VERSION ""

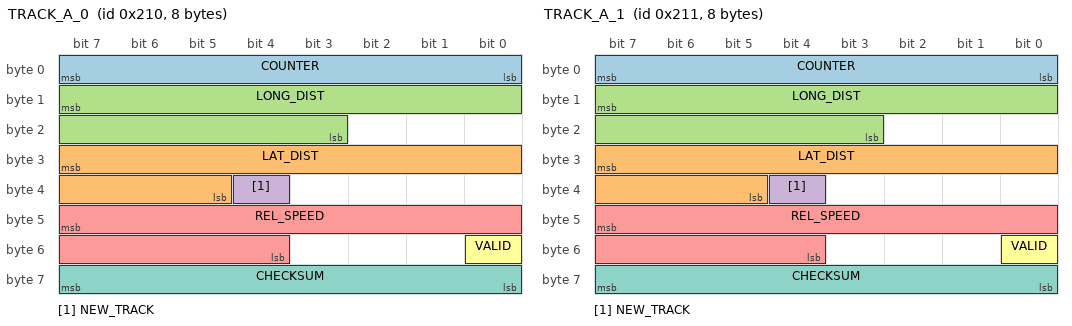
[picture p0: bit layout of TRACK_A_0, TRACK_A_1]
BO_ 528 TRACK_A_0: 8 XXX
 SG_ COUNTER : 7|8@0+ (1,0) [0|255] "" XXX
 SG_ LAT_DIST : 31|11@0- (0.04,0) [-50|50] "m" XXX
 SG_ LONG_DIST : 15|13@0+ (0.04,0) [0|300] "m" XXX
 SG_ NEW_TRACK : 36|1@0+ (1,0) [0|1] "" XXX
 SG_ REL_SPEED : 47|12@0- (0.025,0) [-100|100] "m/s" XXX
 SG_ VALID : 48|1@0+ (1,0) [0|1] "" XXX
 SG_ CHECKSUM : 63|8@0+ (1,0) [0|255] "" XXX

BO_ 529 TRACK_A_1: 8 XXX
 SG_ COUNTER : 7|8@0+ (1,0) [0|255] "" XXX
 SG_ LAT_DIST : 31|11@0- (0.04,0) [-50|50] "m" XXX
 SG_ LONG_DIST : 15|13@0+ (0.04,0) [0|300] "m" XXX
 SG_ NEW_TRACK : 36|1@0+ (1,0) [0|1] "" XXX
 SG_ REL_SPEED : 47|12@0- (0.025,0) [-100|100] "m/s" XXX
 SG_ VALID : 48|1@0+ (1,0) [0|1] "" XXX
 SG_ CHECKSUM : 63|8@0+ (1,0) [0|255] "" XXX

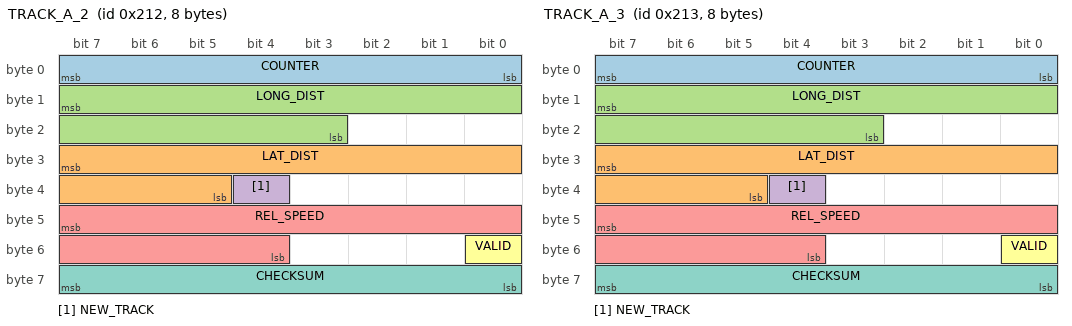
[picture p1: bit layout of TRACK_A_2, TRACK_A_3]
BO_ 530 TRACK_A_2: 8 XXX
 SG_ COUNTER : 7|8@0+ (1,0) [0|255] "" XXX
 SG_ LAT_DIST : 31|11@0- (0.04,0) [-50|50] "m" XXX
 SG_ LONG_DIST : 15|13@0+ (0.04,0) [0|300] "m" XXX
 SG_ NEW_TRACK : 36|1@0+ (1,0) [0|1] "" XXX
 SG_ REL_SPEED : 47|12@0- (0.025,0) [-100|100] "m/s" XXX
 SG_ VALID : 48|1@0+ (1,0) [0|1] "" XXX
 SG_ CHECKSUM : 63|8@0+ (1,0) [0|255] "" XXX

BO_ 531 TRACK_A_3: 8 XXX
 SG_ COUNTER : 7|8@0+ (1,0) [0|255] "" XXX
 SG_ LAT_DIST : 31|11@0- (0.04,0) [-50|50] "m" XXX
 SG_ LONG_DIST : 15|13@0+ (0.04,0) [0|300] "m" XXX
 SG_ NEW_TRACK : 36|1@0+ (1,0) [0|1] "" XXX
 SG_ REL_SPEED : 47|12@0- (0.025,0) [-100|100] "m/s" XXX
 SG_ VALID : 48|1@0+ (1,0) [0|1] "" XXX
 SG_ CHECKSUM : 63|8@0+ (1,0) [0|255] "" XXX

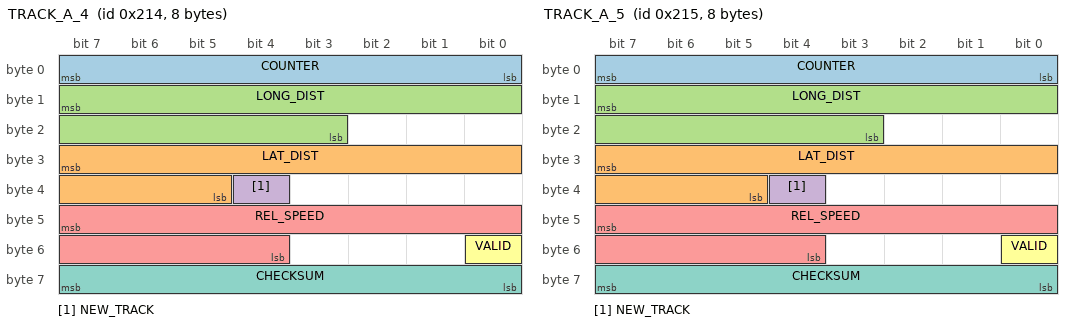
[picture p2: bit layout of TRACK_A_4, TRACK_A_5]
BO_ 532 TRACK_A_4: 8 XXX
 SG_ COUNTER : 7|8@0+ (1,0) [0|255] "" XXX
 SG_ LAT_DIST : 31|11@0- (0.04,0) [-50|50] "m" XXX
 SG_ LONG_DIST : 15|13@0+ (0.04,0) [0|300] "m" XXX
 SG_ NEW_TRACK : 36|1@0+ (1,0) [0|1] "" XXX
 SG_ REL_SPEED : 47|12@0- (0.025,0) [-100|100] "m/s" XXX
 SG_ VALID : 48|1@0+ (1,0) [0|1] "" XXX
 SG_ CHECKSUM : 63|8@0+ (1,0) [0|255] "" XXX

BO_ 533 TRACK_A_5: 8 XXX
 SG_ COUNTER : 7|8@0+ (1,0) [0|255] "" XXX
 SG_ LAT_DIST : 31|11@0- (0.04,0) [-50|50] "m" XXX
 SG_ LONG_DIST : 15|13@0+ (0.04,0) [0|300] "m" XXX
 SG_ NEW_TRACK : 36|1@0+ (1,0) [0|1] "" XXX
 SG_ REL_SPEED : 47|12@0- (0.025,0) [-100|100] "m/s" XXX
 SG_ VALID : 48|1@0+ (1,0) [0|1] "" XXX
 SG_ CHECKSUM : 63|8@0+ (1,0) [0|255] "" XXX

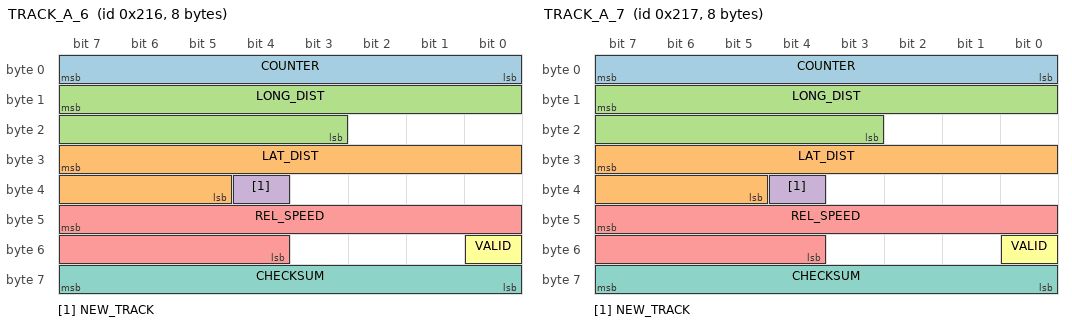
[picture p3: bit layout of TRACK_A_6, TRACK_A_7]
BO_ 534 TRACK_A_6: 8 XXX
 SG_ COUNTER : 7|8@0+ (1,0) [0|255] "" XXX
 SG_ LAT_DIST : 31|11@0- (0.04,0) [-50|50] "m" XXX
 SG_ LONG_DIST : 15|13@0+ (0.04,0) [0|300] "m" XXX
 SG_ NEW_TRACK : 36|1@0+ (1,0) [0|1] "" XXX
 SG_ REL_SPEED : 47|12@0- (0.025,0) [-100|100] "m/s" XXX
 SG_ VALID : 48|1@0+ (1,0) [0|1] "" XXX
 SG_ CHECKSUM : 63|8@0+ (1,0) [0|255] "" XXX

BO_ 535 TRACK_A_7: 8 XXX
 SG_ COUNTER : 7|8@0+ (1,0) [0|255] "" XXX
 SG_ LAT_DIST : 31|11@0- (0.04,0) [-50|50] "m" XXX
 SG_ LONG_DIST : 15|13@0+ (0.04,0) [0|300] "m" XXX
 SG_ NEW_TRACK : 36|1@0+ (1,0) [0|1] "" XXX
 SG_ REL_SPEED : 47|12@0- (0.025,0) [-100|100] "m/s" XXX
 SG_ VALID : 48|1@0+ (1,0) [0|1] "" XXX
 SG_ CHECKSUM : 63|8@0+ (1,0) [0|255] "" XXX

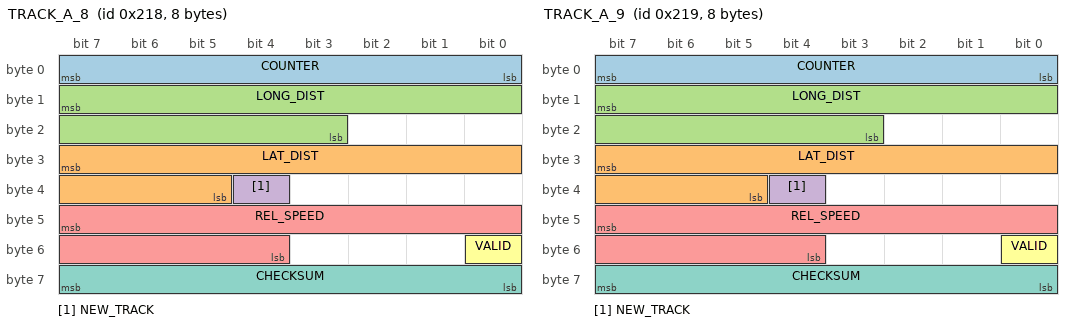
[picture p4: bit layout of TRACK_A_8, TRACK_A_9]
BO_ 536 TRACK_A_8: 8 XXX
 SG_ COUNTER : 7|8@0+ (1,0) [0|255] "" XXX
 SG_ LAT_DIST : 31|11@0- (0.04,0) [-50|50] "m" XXX
 SG_ LONG_DIST : 15|13@0+ (0.04,0) [0|300] "m" XXX
 SG_ NEW_TRACK : 36|1@0+ (1,0) [0|1] "" XXX
 SG_ REL_SPEED : 47|12@0- (0.025,0) [-100|100] "m/s" XXX
 SG_ VALID : 48|1@0+ (1,0) [0|1] "" XXX
 SG_ CHECKSUM : 63|8@0+ (1,0) [0|255] "" XXX

BO_ 537 TRACK_A_9: 8 XXX
 SG_ COUNTER : 7|8@0+ (1,0) [0|255] "" XXX
 SG_ LAT_DIST : 31|11@0- (0.04,0) [-50|50] "m" XXX
 SG_ LONG_DIST : 15|13@0+ (0.04,0) [0|300] "m" XXX
 SG_ NEW_TRACK : 36|1@0+ (1,0) [0|1] "" XXX
 SG_ REL_SPEED : 47|12@0- (0.025,0) [-100|100] "m/s" XXX
 SG_ VALID : 48|1@0+ (1,0) [0|1] "" XXX
 SG_ CHECKSUM : 63|8@0+ (1,0) [0|255] "" XXX

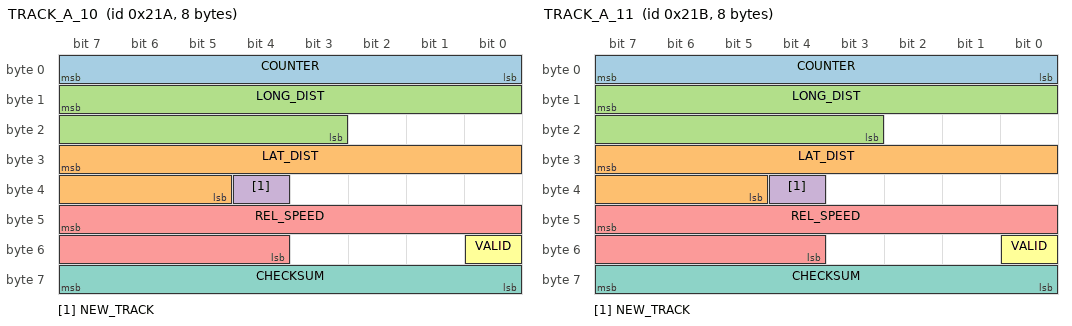
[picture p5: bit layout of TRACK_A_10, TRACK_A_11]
BO_ 538 TRACK_A_10: 8 XXX
 SG_ COUNTER : 7|8@0+ (1,0) [0|255] "" XXX
 SG_ LAT_DIST : 31|11@0- (0.04,0) [-50|50] "m" XXX
 SG_ LONG_DIST : 15|13@0+ (0.04,0) [0|300] "m" XXX
 SG_ NEW_TRACK : 36|1@0+ (1,0) [0|1] "" XXX
 SG_ REL_SPEED : 47|12@0- (0.025,0) [-100|100] "m/s" XXX
 SG_ VALID : 48|1@0+ (1,0) [0|1] "" XXX
 SG_ CHECKSUM : 63|8@0+ (1,0) [0|255] "" XXX

BO_ 539 TRACK_A_11: 8 XXX
 SG_ COUNTER : 7|8@0+ (1,0) [0|255] "" XXX
 SG_ LAT_DIST : 31|11@0- (0.04,0) [-50|50] "m" XXX
 SG_ LONG_DIST : 15|13@0+ (0.04,0) [0|300] "m" XXX
 SG_ NEW_TRACK : 36|1@0+ (1,0) [0|1] "" XXX
 SG_ REL_SPEED : 47|12@0- (0.025,0) [-100|100] "m/s" XXX
 SG_ VALID : 48|1@0+ (1,0) [0|1] "" XXX
 SG_ CHECKSUM : 63|8@0+ (1,0) [0|255] "" XXX

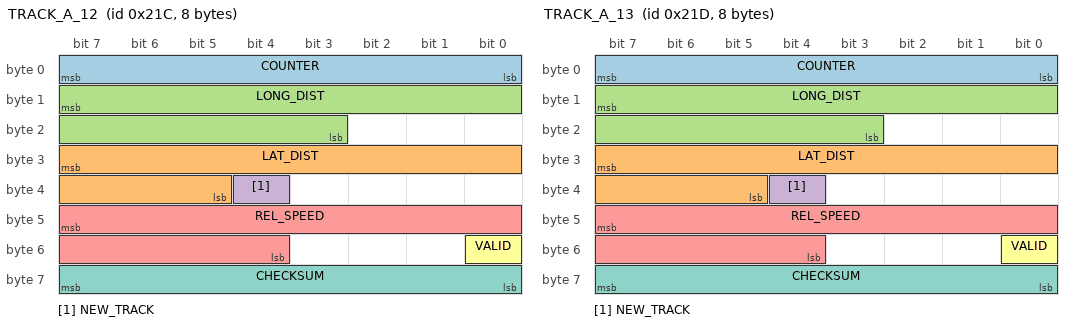
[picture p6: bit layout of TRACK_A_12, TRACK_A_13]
BO_ 540 TRACK_A_12: 8 XXX
 SG_ COUNTER : 7|8@0+ (1,0) [0|255] "" XXX
 SG_ LAT_DIST : 31|11@0- (0.04,0) [-50|50] "m" XXX
 SG_ LONG_DIST : 15|13@0+ (0.04,0) [0|300] "m" XXX
 SG_ NEW_TRACK : 36|1@0+ (1,0) [0|1] "" XXX
 SG_ REL_SPEED : 47|12@0- (0.025,0) [-100|100] "m/s" XXX
 SG_ VALID : 48|1@0+ (1,0) [0|1] "" XXX
 SG_ CHECKSUM : 63|8@0+ (1,0) [0|255] "" XXX

BO_ 541 TRACK_A_13: 8 XXX
 SG_ COUNTER : 7|8@0+ (1,0) [0|255] "" XXX
 SG_ LAT_DIST : 31|11@0- (0.04,0) [-50|50] "m" XXX
 SG_ LONG_DIST : 15|13@0+ (0.04,0) [0|300] "m" XXX
 SG_ NEW_TRACK : 36|1@0+ (1,0) [0|1] "" XXX
 SG_ REL_SPEED : 47|12@0- (0.025,0) [-100|100] "m/s" XXX
 SG_ VALID : 48|1@0+ (1,0) [0|1] "" XXX
 SG_ CHECKSUM : 63|8@0+ (1,0) [0|255] "" XXX

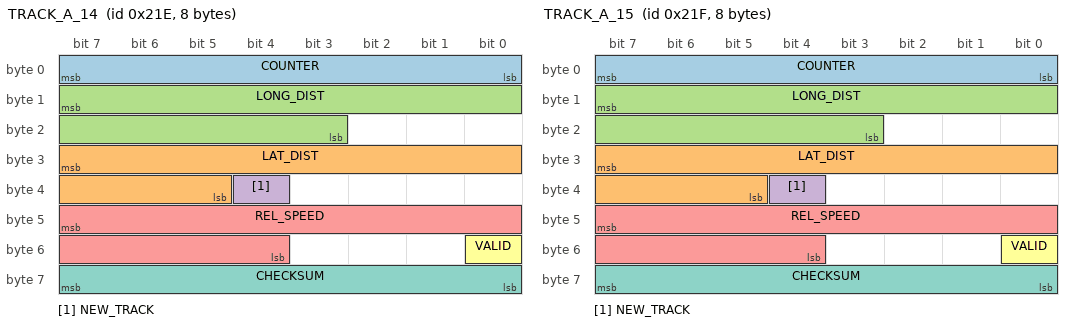
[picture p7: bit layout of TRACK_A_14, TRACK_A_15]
BO_ 542 TRACK_A_14: 8 XXX
 SG_ COUNTER : 7|8@0+ (1,0) [0|255] "" XXX
 SG_ LAT_DIST : 31|11@0- (0.04,0) [-50|50] "m" XXX
 SG_ LONG_DIST : 15|13@0+ (0.04,0) [0|300] "m" XXX
 SG_ NEW_TRACK : 36|1@0+ (1,0) [0|1] "" XXX
 SG_ REL_SPEED : 47|12@0- (0.025,0) [-100|100] "m/s" XXX
 SG_ VALID : 48|1@0+ (1,0) [0|1] "" XXX
 SG_ CHECKSUM : 63|8@0+ (1,0) [0|255] "" XXX

BO_ 543 TRACK_A_15: 8 XXX
 SG_ COUNTER : 7|8@0+ (1,0) [0|255] "" XXX
 SG_ LAT_DIST : 31|11@0- (0.04,0) [-50|50] "m" XXX
 SG_ LONG_DIST : 15|13@0+ (0.04,0) [0|300] "m" XXX
 SG_ NEW_TRACK : 36|1@0+ (1,0) [0|1] "" XXX
 SG_ REL_SPEED : 47|12@0- (0.025,0) [-100|100] "m/s" XXX
 SG_ VALID : 48|1@0+ (1,0) [0|1] "" XXX
 SG_ CHECKSUM : 63|8@0+ (1,0) [0|255] "" XXX

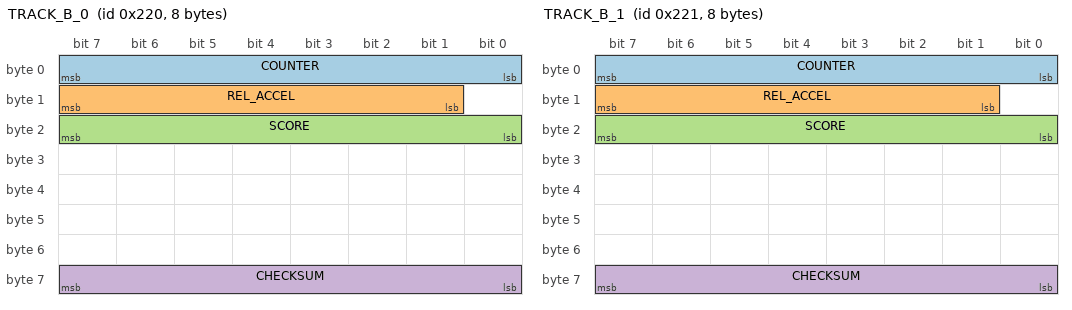
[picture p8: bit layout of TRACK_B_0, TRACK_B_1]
BO_ 544 TRACK_B_0: 8 XXX
 SG_ COUNTER : 7|8@0+ (1,0) [0|255] "" XXX
 SG_ REL_ACCEL : 15|7@0- (1,0) [-64|63] "" XXX
 SG_ SCORE : 23|8@0+ (1,0) [0|100] "" XXX
 SG_ CHECKSUM : 63|8@0+ (1,0) [0|255] "" XXX

BO_ 545 TRACK_B_1: 8 XXX
 SG_ COUNTER : 7|8@0+ (1,0) [0|255] "" XXX
 SG_ REL_ACCEL : 15|7@0- (1,0) [-64|63] "" XXX
 SG_ SCORE : 23|8@0+ (1,0) [0|100] "" XXX
 SG_ CHECKSUM : 63|8@0+ (1,0) [0|255] "" XXX

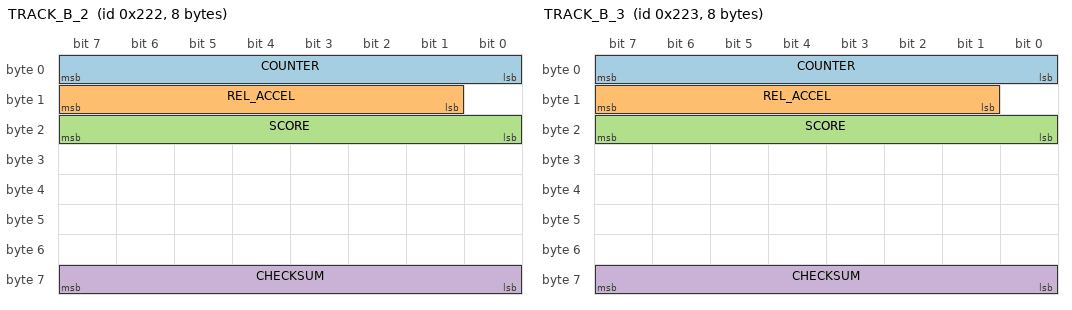
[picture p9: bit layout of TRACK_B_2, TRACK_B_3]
BO_ 546 TRACK_B_2: 8 XXX
 SG_ COUNTER : 7|8@0+ (1,0) [0|255] "" XXX
 SG_ REL_ACCEL : 15|7@0- (1,0) [-64|63] "" XXX
 SG_ SCORE : 23|8@0+ (1,0) [0|100] "" XXX
 SG_ CHECKSUM : 63|8@0+ (1,0) [0|255] "" XXX

BO_ 547 TRACK_B_3: 8 XXX
 SG_ COUNTER : 7|8@0+ (1,0) [0|255] "" XXX
 SG_ REL_ACCEL : 15|7@0- (1,0) [-64|63] "" XXX
 SG_ SCORE : 23|8@0+ (1,0) [0|100] "" XXX
 SG_ CHECKSUM : 63|8@0+ (1,0) [0|255] "" XXX

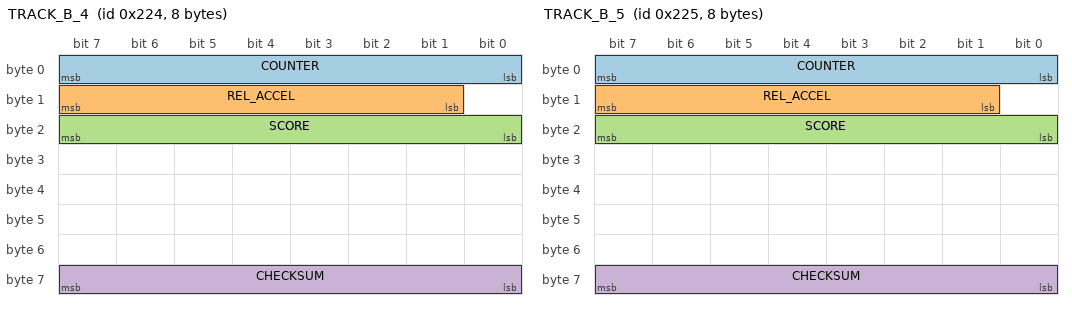
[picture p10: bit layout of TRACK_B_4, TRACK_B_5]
BO_ 548 TRACK_B_4: 8 XXX
 SG_ COUNTER : 7|8@0+ (1,0) [0|255] "" XXX
 SG_ REL_ACCEL : 15|7@0- (1,0) [-64|63] "" XXX
 SG_ SCORE : 23|8@0+ (1,0) [0|100] "" XXX
 SG_ CHECKSUM : 63|8@0+ (1,0) [0|255] "" XXX

BO_ 549 TRACK_B_5: 8 XXX
 SG_ COUNTER : 7|8@0+ (1,0) [0|255] "" XXX
 SG_ REL_ACCEL : 15|7@0- (1,0) [-64|63] "" XXX
 SG_ SCORE : 23|8@0+ (1,0) [0|100] "" XXX
 SG_ CHECKSUM : 63|8@0+ (1,0) [0|255] "" XXX

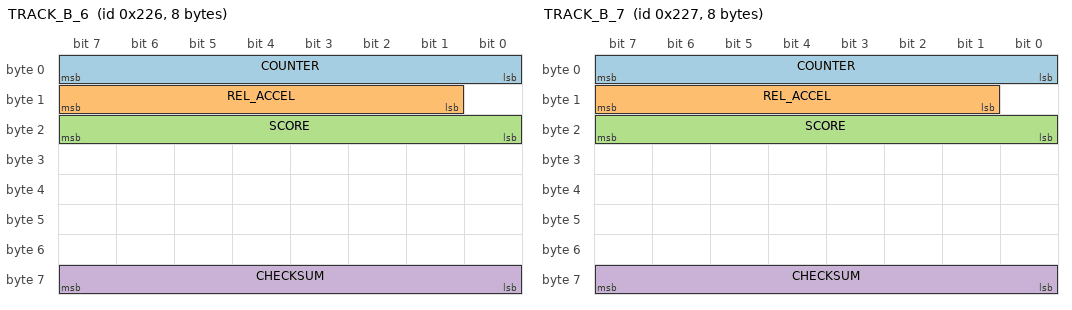
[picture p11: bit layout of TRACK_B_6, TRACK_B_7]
BO_ 550 TRACK_B_6: 8 XXX
 SG_ COUNTER : 7|8@0+ (1,0) [0|255] "" XXX
 SG_ REL_ACCEL : 15|7@0- (1,0) [-64|63] "" XXX
 SG_ SCORE : 23|8@0+ (1,0) [0|100] "" XXX
 SG_ CHECKSUM : 63|8@0+ (1,0) [0|255] "" XXX

BO_ 551 TRACK_B_7: 8 XXX
 SG_ COUNTER : 7|8@0+ (1,0) [0|255] "" XXX
 SG_ REL_ACCEL : 15|7@0- (1,0) [-64|63] "" XXX
 SG_ SCORE : 23|8@0+ (1,0) [0|100] "" XXX
 SG_ CHECKSUM : 63|8@0+ (1,0) [0|255] "" XXX

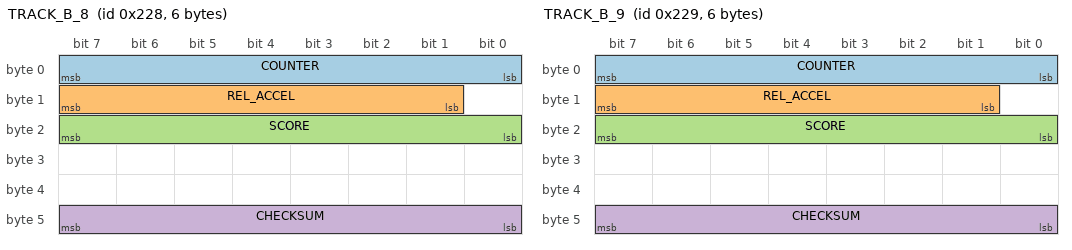
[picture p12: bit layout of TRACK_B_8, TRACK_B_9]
BO_ 552 TRACK_B_8: 6 XXX
 SG_ COUNTER : 7|8@0+ (1,0) [0|255] "" XXX
 SG_ REL_ACCEL : 15|7@0- (1,0) [-64|63] "" XXX
 SG_ SCORE : 23|8@0+ (1,0) [0|100] "" XXX
 SG_ CHECKSUM : 47|8@0+ (1,0) [0|255] "" XXX

BO_ 553 TRACK_B_9: 6 XXX
 SG_ COUNTER : 7|8@0+ (1,0) [0|255] "" XXX
 SG_ REL_ACCEL : 15|7@0- (1,0) [-64|63] "" XXX
 SG_ SCORE : 23|8@0+ (1,0) [0|100] "" XXX
 SG_ CHECKSUM : 47|8@0+ (1,0) [0|255] "" XXX

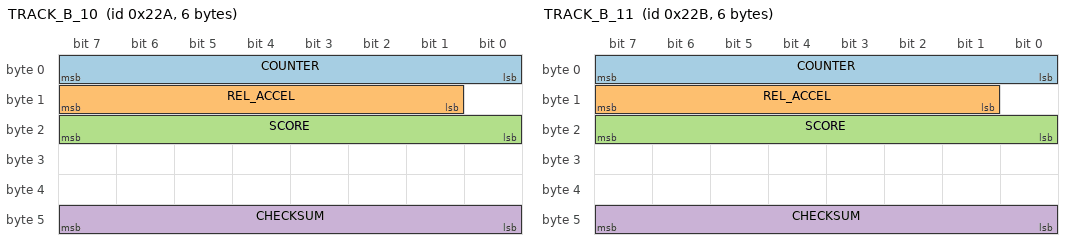
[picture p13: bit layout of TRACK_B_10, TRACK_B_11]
BO_ 554 TRACK_B_10: 6 XXX
 SG_ COUNTER : 7|8@0+ (1,0) [0|255] "" XXX
 SG_ REL_ACCEL : 15|7@0- (1,0) [-64|63] "" XXX
 SG_ SCORE : 23|8@0+ (1,0) [0|100] "" XXX
 SG_ CHECKSUM : 47|8@0+ (1,0) [0|255] "" XXX

BO_ 555 TRACK_B_11: 6 XXX
 SG_ COUNTER : 7|8@0+ (1,0) [0|255] "" XXX
 SG_ REL_ACCEL : 15|7@0- (1,0) [-64|63] "" XXX
 SG_ SCORE : 23|8@0+ (1,0) [0|100] "" XXX
 SG_ CHECKSUM : 47|8@0+ (1,0) [0|255] "" XXX

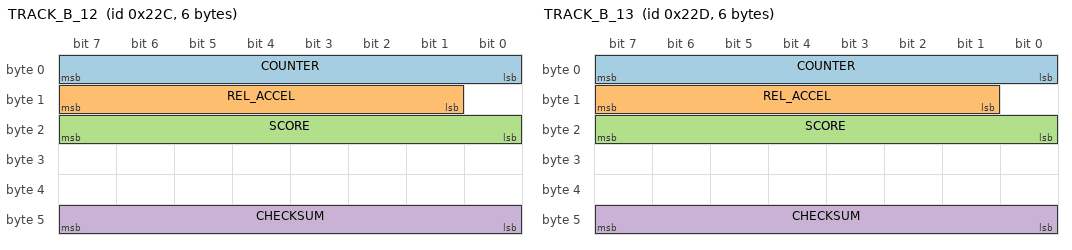
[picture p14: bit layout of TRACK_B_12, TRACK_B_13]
BO_ 556 TRACK_B_12: 6 XXX
 SG_ COUNTER : 7|8@0+ (1,0) [0|255] "" XXX
 SG_ REL_ACCEL : 15|7@0- (1,0) [-64|63] "" XXX
 SG_ SCORE : 23|8@0+ (1,0) [0|100] "" XXX
 SG_ CHECKSUM : 47|8@0+ (1,0) [0|255] "" XXX

BO_ 557 TRACK_B_13: 6 XXX
 SG_ COUNTER : 7|8@0+ (1,0) [0|255] "" XXX
 SG_ REL_ACCEL : 15|7@0- (1,0) [-64|63] "" XXX
 SG_ SCORE : 23|8@0+ (1,0) [0|100] "" XXX
 SG_ CHECKSUM : 47|8@0+ (1,0) [0|255] "" XXX

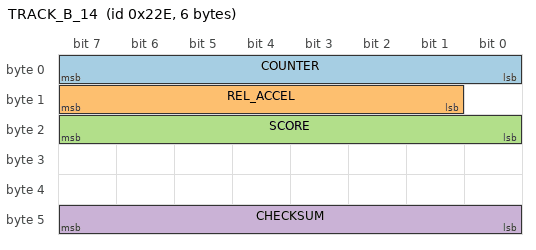
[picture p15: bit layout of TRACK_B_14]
BO_ 558 TRACK_B_14: 6 XXX
 SG_ COUNTER : 7|8@0+ (1,0) [0|255] "" XXX
 SG_ REL_ACCEL : 15|7@0- (1,0) [-64|63] "" XXX
 SG_ SCORE : 23|8@0+ (1,0) [0|100] "" XXX
 SG_ CHECKSUM : 47|8@0+ (1,0) [0|255] "" XXX

CM_ "AUTOGENERATED FILE, DO NOT EDIT";

CM_ "Imported file _stellantis_common.dbc starts here";
CM_ SG_ 258 STEERING_ANGLE_HP "Steering angle high precision";
CM_ SG_ 264 ENGINE_TORQUE "Effective engine torque";
CM_ SG_ 264 EXPECTED_ENGINE_TORQUE "Expected Engine Torque based on target engine speed";
CM_ SG_ 678 LKAS_ICON_COLOR "3 is yellow, 2 is green, 1 is white, 0 is null";
CM_ SG_ 678 LKAS_LANE_LINES "0x01 transparent lines, 0x02 left white, 0x03 right white, 0x04 left yellow with car on top, 0x05 left yellow with car on top, 0x06 both white, 0x07 left yellow, 0x08 left yellow right white, 0x09 right yellow, 0x0a right yellow left white, 0x0b left yellow with car on top right white, 0x0c right yellow with car on top left white, (0x00, 0x0d, 0x0e, 0x0f) null";
CM_ SG_ 678 LKAS_ALERTS "(0x01, 0x02) lane sense off, (0x03, 0x04, 0x06) place hands on steering wheel, 0x07 lane departure detected + place hands on steering wheel, (0x08, 0x09) lane sense unavailable + clean front windshield, 0x0b lane sense and auto high beam unavailable + clean front windshield, 0x0c lane sense unavailable + service required, (0x00, 0x05, 0x0a, 0x0d, 0x0e, 0x0f) null";

CM_ "chrysler_pacifica_2017_hybrid.dbc starts here";

CM_ SG_ 653 BRAKE_PRESSURE "max seems to be 148";
CM_ SG_ 746 PRNDL "5=L, 4=D, 3=N, 2=R, 1=P";
CM_ SG_ 320 BRAKE_PRESSED_2 "Value is 5 when brake is pressed by human, 1 when ACC brake";
CM_ SG_ 320 BRAKE_PRESSED_ACC "set when ACC brakes";
CM_ SG_ 792 TURN_SIGNALS "1=Left, 2=Right";
CM_ SG_ 264 ACCEL_PEDAL "not in ACC so seems to be actual pedal. Use for gasPressed";
CM_ SG_ 544 LKAS_STATE "2 when autopark has control, 8 when is actuatable by lkas, 4 when there is a fault";
CM_ SG_ 658 LKAS_STEERING_TORQUE "Most sent by stock system is 1024+-230. + is left. typically changes by 2 or 3 each 0.01s";
CM_ SG_ 678 LKAS_ICON_COLOR "3 is yellow, 2 is green, 1 is white, 0 is null";
CM_ SG_ 678 LKAS_LANE_LINES "0x01 transparent lines, 0x02 left white, 0x03 right white, 0x04 left yellow with car on top, 0x05 left yellow with car on top, 0x06 both white, 0x07 left yellow, 0x08 left yellow right white, 0x09 right yellow, 0x0a right yellow left white, 0x0b left yellow with car on top right white, 0x0c right yellow with car on top left white, (0x00, 0x0d, 0x0e, 0x0f) null";
CM_ SG_ 678 LKAS_ALERTS "(0x01, 0x02) lane sense off, (0x03, 0x04, 0x06) place hands on steering wheel, 0x07 lane departure detected + place hands on steering wheel, (0x08, 0x09) lane sense unavailable + clean front windshield, 0x0b lane sense and auto high beam unavailable + clean front windshield, 0x0c lane sense unavailable + service required, (0x00, 0x05, 0x0a, 0x0d, 0x0e, 0x0f) null";
CM_ SG_ 705 AUTO_PARK_TOGGLE_1 "set briefly when turning on or off self-parking";
CM_ SG_ 671 AUTO_PARK_CMD "Request Appears to be in NM";
CM_ SG_ 671 AUTO_PARK_STATUS "1 = IDLE / NO REQUEST 9 = START REQUEST 10 = REQUEST MODE 11 = REQUEST MODE";
CM_ SG_ 826 AUTO_PARK_GEAR_1 "Reverse=0, Forward=f";
CM_ SG_ 826 AUTO_PARK_GEAR_2 "Reverse=0, Forward=f";
CM_ SG_ 826 AUTO_PARK_GEAR_3 "Reverse=0, Forward=f";
CM_ SG_ 332 STEER_ANGLE_2 "slightly lags the other steer_angle signal. also more noisy.";
CM_ SG_ 608 PARKSENSE_DISABLED "set if parksense is disabled";
CM_ SG_ 729 LKAS_STATUS_OK "Set to 0x0820 when LKAS system is plugged in.";
CM_ SG_ 825 BEEP_339 "sent every 0.5s. 0050 is no beep. To beep send 4355 or 4155. Used by ParkSense warning.";
CM_ SG_ 270 ELECTRIC_MOTOR "0x7fff indicates electric motor not in use";
CM_ SG_ 291 ENERGY_GAIN_LOSS "unsure what this actually is";
CM_ SG_ 291 ENERGY_SMOOTHER_CURVE "unsure what it is, but smoother";
CM_ SG_ 308 ACCEL_134 "only set when human presses accel pedal";
CM_ SG_ 532 NOISY_SLOWLY_DECREASING "perhaps battery but do not know";
CM_ SG_ 816 TRACTION_OFF "set when traction off button is enabled";
CM_ SG_ 816 TOGGLE_PARKSENSE "sending 3000071ec0ff9000 enables or disables parksense";
CM_ SG_ 324 SPEED_2 "signal is approx half other speeds";
CM_ SG_ 501 ACC_SPEED_CONFIG_KPH "speed configured for ACC";
CM_ SG_ 501 ACC_SPEED_CONFIG_MPH "speed configured for ACC";
CM_ SG_ 501 CRUISE_STATE "may just be an icon, but seems to indicate different cruise modes: ACC and Non-ACC and engaged state for both.";
CM_ SG_ 625 SPEED "zero on non-acc drives";

VAL_ 513 STATE 5 "FAULT_TIMEOUT" 4 "FAULT_STARTUP" 3 "FAULT_SCE" 2 "FAULT_SEND" 1 "FAULT_BAD_CHECKSUM" 0 "NO_FAULT" ;

VAL_ 780 CRUISE_SPEED 255 "no_speed" 252 "stopped";
VAL_ 780 HUD_LEAD 3 "acc_off" 2 "solid_car" 1 "dashed_car" 0 "no_car";
VAL_ 884 DASHBOARD_ALERT 0 "none" 51 "acc_problem" 55 "cmbs_problem" 75 "key_not_detected" 79 "fasten_seatbelt" 111 "lkas_problem" 131 "brake_system_problem" 132 "brake_hold_problem" 139 "tbd" 161 "door_open";
VAL_ 891 WIPERS 4 "High" 2 "Low" 0 "Off";

VAL_ 506 FCW 3 "fcw" 2 "fcw" 1 "fcw" 0 "no_fcw";
VAL_ 506 CHIME 4 "double_chime" 3 "single_chime" 2 "continuous_chime" 1 "repeating_chime" 0 "no_chime";
VAL_ 506 AEB_STATUS 3 "aeb_prepare" 2 "aeb_ready" 1 "aeb_braking" 0 "no_aeb";
VAL_ 829 BEEP 3 "single_beep" 2 "triple_beep" 1 "repeated_beep" 0 "no_beep";

VAL_ 399 STEER_STATUS 5 "tmp_fault" 4 "no_torque_alert_2" 2 "no_torque_alert_1" 0 "normal" ;
VAL_ 419 GEAR_SHIFTER 10 "S" 4 "D" 3 "N" 2 "R" 1 "P" ;
VAL_ 450 EPB_STATE 3 "engaged" 2 "disengaging" 1 "engaging" 0 "disengaged" ;
VAL_ 545 ECON_ON_2 0 "off" 3 "on" ;
VAL_ 662 CRUISE_BUTTONS 7 "tbd" 6 "tbd" 5 "tbd" 4 "accel_res" 3 "decel_set" 2 "cancel" 1 "main" 0 "none" ;
VAL_ 662 CRUISE_SETTING 3 "distance_adj" 2 "tbd" 1 "lkas_button" 0 "none" ;
VAL_ 806 CMBS_BUTTON 3 "pressed" 0 "released" ;
